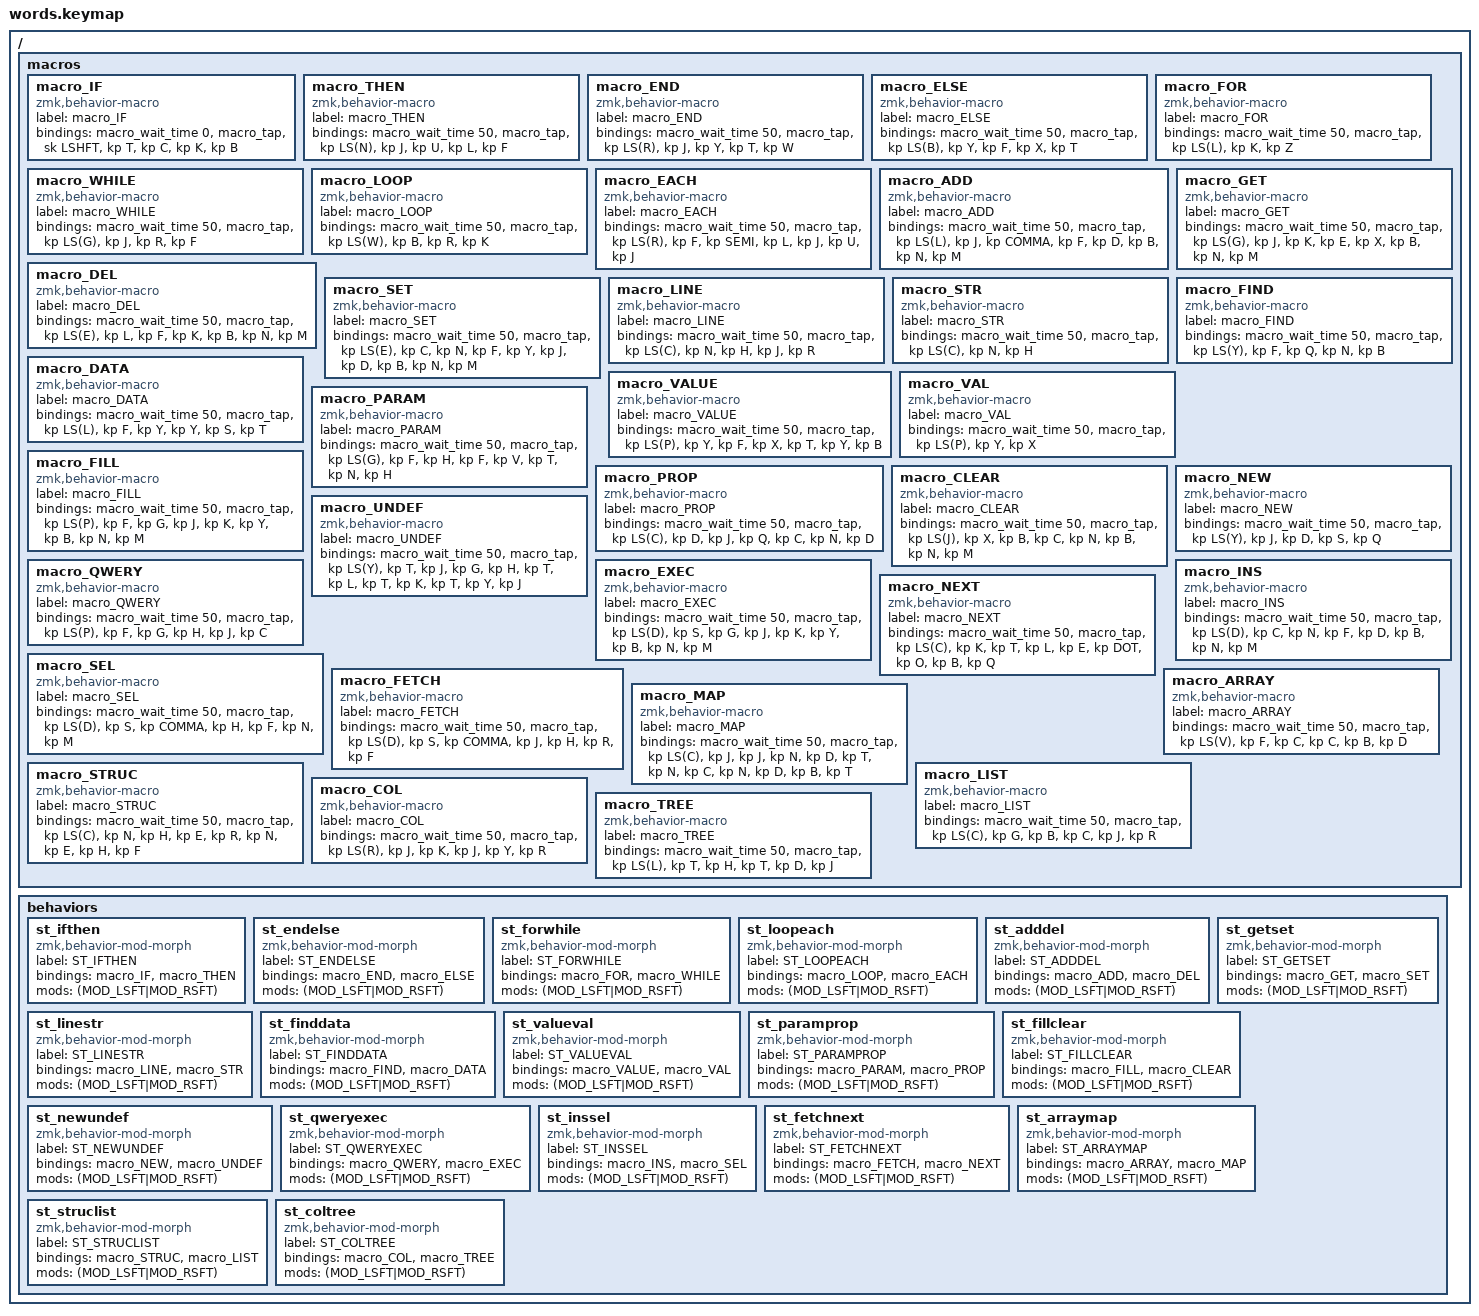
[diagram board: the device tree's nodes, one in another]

/ {
    macros {
        macro_IF: macro_IF {
            label = "macro_IF";
            compatible = "zmk,behavior-macro";
            #binding-cells = <0>;
            bindings
                = <&macro_wait_time 0>
                , <&macro_tap &sk LSHFT &kp T &kp C &kp K &kp B>
                ;
        };
        macro_THEN: macro_THEN {
            label = "macro_THEN";
            compatible = "zmk,behavior-macro";
            #binding-cells = <0>;
            bindings
                = <&macro_wait_time 50>
                , <&macro_tap &kp LS(N) &kp J &kp U &kp L &kp F>
                ;
        };
    };
};
/ {
    behaviors {
        st_ifthen: st_ifthen {
            compatible = "zmk,behavior-mod-morph";
            label = "ST_IFTHEN";
            #binding-cells = <0>;
            bindings = <&macro_IF>, <&macro_THEN>;
            mods = <(MOD_LSFT|MOD_RSFT)>;
        };
    };
};
/ {
    macros {
        macro_END: macro_END {
            label = "macro_END";
            compatible = "zmk,behavior-macro";
            #binding-cells = <0>;
            bindings
                = <&macro_wait_time 50>
                , <&macro_tap &kp LS(R) &kp J &kp Y &kp T &kp W>
                ;
        };
        macro_ELSE: macro_ELSE {
            label = "macro_ELSE";
            compatible = "zmk,behavior-macro";
            #binding-cells = <0>;
            bindings
                = <&macro_wait_time 50>
                , <&macro_tap &kp LS(B) &kp Y &kp F &kp X &kp T>
                ;
        };
    };
};
/ {
    behaviors {
        st_endelse: st_endelse {
            compatible = "zmk,behavior-mod-morph";
            label = "ST_ENDELSE";
            #binding-cells = <0>;
            bindings = <&macro_END>, <&macro_ELSE>;
            mods = <(MOD_LSFT|MOD_RSFT)>;
        };
    };
};
/ {
    macros {
        macro_FOR: macro_FOR {
            label = "macro_FOR";
            compatible = "zmk,behavior-macro";
            #binding-cells = <0>;
            bindings
                = <&macro_wait_time 50>
                , <&macro_tap &kp LS(L) &kp K &kp Z>
                ;
        };
        macro_WHILE: macro_WHILE {
            label = "macro_WHILE";
            compatible = "zmk,behavior-macro";
            #binding-cells = <0>;
            bindings
                = <&macro_wait_time 50>
                , <&macro_tap &kp LS(G) &kp J &kp R &kp F>
                ;
        };
    };
};
/ {
    behaviors {
        st_forwhile: st_forwhile {
            compatible = "zmk,behavior-mod-morph";
            label = "ST_FORWHILE";
            #binding-cells = <0>;
            bindings = <&macro_FOR>, <&macro_WHILE>;
            mods = <(MOD_LSFT|MOD_RSFT)>;
        };
    };
};
/ {
    macros {
        macro_LOOP: macro_LOOP {
            label = "macro_LOOP";
            compatible = "zmk,behavior-macro";
            #binding-cells = <0>;
            bindings
                = <&macro_wait_time 50>
                , <&macro_tap &kp LS(W) &kp B &kp R &kp K>
                ;
        };
        macro_EACH: macro_EACH {
            label = "macro_EACH";
            compatible = "zmk,behavior-macro";
            #binding-cells = <0>;
            bindings
                = <&macro_wait_time 50>
                , <&macro_tap &kp LS(R) &kp F &kp SEMI &kp L &kp J &kp U &kp J>
                ;
        };
    };
};
/ {
    behaviors {
        st_loopeach: st_loopeach {
            compatible = "zmk,behavior-mod-morph";
            label = "ST_LOOPEACH";
            #binding-cells = <0>;
            bindings = <&macro_LOOP>, <&macro_EACH>;
            mods = <(MOD_LSFT|MOD_RSFT)>;
        };
    };
};
/ {
    macros {
        macro_ADD: macro_ADD {
            label = "macro_ADD";
            compatible = "zmk,behavior-macro";
            #binding-cells = <0>;
            bindings
                = <&macro_wait_time 50>
                , <&macro_tap &kp LS(L) &kp J &kp COMMA &kp F &kp D &kp B &kp N &kp M>
                ;
        };
        macro_DEL: macro_DEL {
            label = "macro_DEL";
            compatible = "zmk,behavior-macro";
            #binding-cells = <0>;
            bindings
                = <&macro_wait_time 50>
                , <&macro_tap &kp LS(E) &kp L &kp F &kp K &kp B &kp N &kp M>
                ;
        };
    };
};
/ {
    behaviors {
        st_adddel: st_adddel {
            compatible = "zmk,behavior-mod-morph";
            label = "ST_ADDDEL";
            #binding-cells = <0>;
            bindings = <&macro_ADD>, <&macro_DEL>;
            mods = <(MOD_LSFT|MOD_RSFT)>;
        };
    };
};
/ {
    macros {
        macro_GET: macro_GET {
            label = "macro_GET";
            compatible = "zmk,behavior-macro";
            #binding-cells = <0>;
            bindings
                = <&macro_wait_time 50>
                , <&macro_tap &kp LS(G) &kp J &kp K &kp E &kp X &kp B &kp N &kp M>
                ;
        };
        macro_SET: macro_SET {
            label = "macro_SET";
            compatible = "zmk,behavior-macro";
            #binding-cells = <0>;
            bindings
                = <&macro_wait_time 50>
                , <&macro_tap &kp LS(E) &kp C &kp N &kp F &kp Y &kp J &kp D &kp B &kp N &kp M>
                ;
        };
    };
};
/ {
    behaviors {
        st_getset: st_getset {
            compatible = "zmk,behavior-mod-morph";
            label = "ST_GETSET";
            #binding-cells = <0>;
            bindings = <&macro_GET>, <&macro_SET>;
            mods = <(MOD_LSFT|MOD_RSFT)>;
        };
    };
};
/ {
    macros {
        macro_LINE: macro_LINE {
            label = "macro_LINE";
            compatible = "zmk,behavior-macro";
            #binding-cells = <0>;
            bindings
                = <&macro_wait_time 50>
                , <&macro_tap &kp LS(C) &kp N &kp H &kp J &kp R>
                ;
        };
        macro_STR: macro_STR {
            label = "macro_STR";
            compatible = "zmk,behavior-macro";
            #binding-cells = <0>;
            bindings
                = <&macro_wait_time 50>
                , <&macro_tap &kp LS(C) &kp N &kp H>
                ;
        };
    };
};
/ {
    behaviors {
        st_linestr: st_linestr {
            compatible = "zmk,behavior-mod-morph";
            label = "ST_LINESTR";
            #binding-cells = <0>;
            bindings = <&macro_LINE>, <&macro_STR>;
            mods = <(MOD_LSFT|MOD_RSFT)>;
        };
    };
};
/ {
    macros {
        macro_FIND: macro_FIND {
            label = "macro_FIND";
            compatible = "zmk,behavior-macro";
            #binding-cells = <0>;
            bindings
                = <&macro_wait_time 50>
                , <&macro_tap &kp LS(Y) &kp F &kp Q &kp N &kp B>
                ;
        };
        macro_DATA: macro_DATA {
            label = "macro_DATA";
            compatible = "zmk,behavior-macro";
            #binding-cells = <0>;
            bindings
                = <&macro_wait_time 50>
                , <&macro_tap &kp LS(L) &kp F &kp Y &kp Y &kp S &kp T>
                ;
        };
    };
};
/ {
    behaviors {
        st_finddata: st_finddata {
            compatible = "zmk,behavior-mod-morph";
            label = "ST_FINDDATA";
            #binding-cells = <0>;
            bindings = <&macro_FIND>, <&macro_DATA>;
            mods = <(MOD_LSFT|MOD_RSFT)>;
        };
    };
};
/ {
    macros {
        macro_VALUE: macro_VALUE {
            label = "macro_VALUE";
            compatible = "zmk,behavior-macro";
            #binding-cells = <0>;
            bindings
                = <&macro_wait_time 50>
                , <&macro_tap &kp LS(P) &kp Y &kp F &kp X &kp T &kp Y &kp B>
                ;
        };
        macro_VAL: macro_VAL {
            label = "macro_VAL";
            compatible = "zmk,behavior-macro";
            #binding-cells = <0>;
            bindings
                = <&macro_wait_time 50>
                , <&macro_tap &kp LS(P) &kp Y &kp X>
                ;
        };
    };
};
/ {
    behaviors {
        st_valueval: st_valueval {
            compatible = "zmk,behavior-mod-morph";
            label = "ST_VALUEVAL";
            #binding-cells = <0>;
            bindings = <&macro_VALUE>, <&macro_VAL>;
            mods = <(MOD_LSFT|MOD_RSFT)>;
        };
    };
};
/ {
    macros {
        macro_PARAM: macro_PARAM {
            label = "macro_PARAM";
            compatible = "zmk,behavior-macro";
            #binding-cells = <0>;
            bindings
                = <&macro_wait_time 50>
                , <&macro_tap &kp LS(G) &kp F &kp H &kp F &kp V &kp T &kp N &kp H>
                ;
        };
        macro_PROP: macro_PROP {
            label = "macro_PROP";
            compatible = "zmk,behavior-macro";
            #binding-cells = <0>;
            bindings
                = <&macro_wait_time 50>
                , <&macro_tap &kp LS(C) &kp D &kp J &kp Q &kp C &kp N &kp D>
                ;
        };
    };
};
/ {
    behaviors {
        st_paramprop: st_paramprop {
            compatible = "zmk,behavior-mod-morph";
            label = "ST_PARAMPROP";
            #binding-cells = <0>;
            bindings = <&macro_PARAM>, <&macro_PROP>;
            mods = <(MOD_LSFT|MOD_RSFT)>;
        };
    };
};
/ {
    macros {
        macro_FILL: macro_FILL {
            label = "macro_FILL";
            compatible = "zmk,behavior-macro";
            #binding-cells = <0>;
            bindings
                = <&macro_wait_time 50>
                , <&macro_tap &kp LS(P) &kp F &kp G &kp J &kp K &kp Y &kp B &kp N &kp M>
                ;
        };
        macro_CLEAR: macro_CLEAR {
            label = "macro_CLEAR";
            compatible = "zmk,behavior-macro";
            #binding-cells = <0>;
            bindings
                = <&macro_wait_time 50>
                , <&macro_tap &kp LS(J) &kp X &kp B &kp C &kp N &kp B &kp N &kp M>
                ;
        };
    };
};
/ {
    behaviors {
        st_fillclear: st_fillclear {
            compatible = "zmk,behavior-mod-morph";
            label = "ST_FILLCLEAR";
            #binding-cells = <0>;
            bindings = <&macro_FILL>, <&macro_CLEAR>;
            mods = <(MOD_LSFT|MOD_RSFT)>;
        };
    };
};
/ {
    macros {
        macro_NEW: macro_NEW {
            label = "macro_NEW";
            compatible = "zmk,behavior-macro";
            #binding-cells = <0>;
            bindings
                = <&macro_wait_time 50>
                , <&macro_tap &kp LS(Y) &kp J &kp D &kp S &kp Q>
                ;
        };
        macro_UNDEF: macro_UNDEF {
            label = "macro_UNDEF";
            compatible = "zmk,behavior-macro";
            #binding-cells = <0>;
            bindings
                = <&macro_wait_time 50>
                , <&macro_tap &kp LS(Y) &kp T &kp J &kp G &kp H &kp T &kp L &kp T &kp K &kp T &kp Y &kp J>
                ;
        };
    };
};
/ {
    behaviors {
        st_newundef: st_newundef {
            compatible = "zmk,behavior-mod-morph";
            label = "ST_NEWUNDEF";
            #binding-cells = <0>;
            bindings = <&macro_NEW>, <&macro_UNDEF>;
            mods = <(MOD_LSFT|MOD_RSFT)>;
        };
    };
};
/ {
    macros {
        macro_QWERY: macro_QWERY {
            label = "macro_QWERY";
            compatible = "zmk,behavior-macro";
            #binding-cells = <0>;
            bindings
                = <&macro_wait_time 50>
                , <&macro_tap &kp LS(P) &kp F &kp G &kp H &kp J &kp C>
                ;
        };
        macro_EXEC: macro_EXEC {
            label = "macro_EXEC";
            compatible = "zmk,behavior-macro";
            #binding-cells = <0>;
            bindings
                = <&macro_wait_time 50>
                , <&macro_tap &kp LS(D) &kp S &kp G &kp J &kp K &kp Y &kp B &kp N &kp M>
                ;
        };
    };
};
/ {
    behaviors {
        st_qweryexec: st_qweryexec {
            compatible = "zmk,behavior-mod-morph";
            label = "ST_QWERYEXEC";
            #binding-cells = <0>;
            bindings = <&macro_QWERY>, <&macro_EXEC>;
            mods = <(MOD_LSFT|MOD_RSFT)>;
        };
    };
};
/ {
    macros {
        macro_INS: macro_INS {
            label = "macro_INS";
            compatible = "zmk,behavior-macro";
            #binding-cells = <0>;
            bindings
                = <&macro_wait_time 50>
                , <&macro_tap &kp LS(D) &kp C &kp N &kp F &kp D &kp B &kp N &kp M>
                ;
        };
        macro_SEL: macro_SEL {
            label = "macro_SEL";
            compatible = "zmk,behavior-macro";
            #binding-cells = <0>;
            bindings
                = <&macro_wait_time 50>
                , <&macro_tap &kp LS(D) &kp S &kp COMMA &kp H &kp F &kp N &kp M>
                ;
        };
    };
};
/ {
    behaviors {
        st_inssel: st_inssel {
            compatible = "zmk,behavior-mod-morph";
            label = "ST_INSSEL";
            #binding-cells = <0>;
            bindings = <&macro_INS>, <&macro_SEL>;
            mods = <(MOD_LSFT|MOD_RSFT)>;
        };
    };
};
/ {
    macros {
        macro_FETCH: macro_FETCH {
            label = "macro_FETCH";
            compatible = "zmk,behavior-macro";
            #binding-cells = <0>;
            bindings
                = <&macro_wait_time 50>
                , <&macro_tap &kp LS(D) &kp S &kp COMMA &kp J &kp H &kp R &kp F>
                ;
        };
        macro_NEXT: macro_NEXT {
            label = "macro_NEXT";
            compatible = "zmk,behavior-macro";
            #binding-cells = <0>;
            bindings
                = <&macro_wait_time 50>
                , <&macro_tap &kp LS(C) &kp K &kp T &kp L &kp E &kp DOT &kp O &kp B &kp Q>
                ;
        };
    };
};
/ {
    behaviors {
        st_fetchnext: st_fetchnext {
            compatible = "zmk,behavior-mod-morph";
            label = "ST_FETCHNEXT";
            #binding-cells = <0>;
            bindings = <&macro_FETCH>, <&macro_NEXT>;
            mods = <(MOD_LSFT|MOD_RSFT)>;
        };
    };
};
/ {
    macros {
        macro_ARRAY: macro_ARRAY {
            label = "macro_ARRAY";
            compatible = "zmk,behavior-macro";
            #binding-cells = <0>;
            bindings
                = <&macro_wait_time 50>
                , <&macro_tap &kp LS(V) &kp F &kp C &kp C &kp B &kp D>
                ;
        };
        macro_MAP: macro_MAP {
            label = "macro_MAP";
            compatible = "zmk,behavior-macro";
            #binding-cells = <0>;
            bindings
                = <&macro_wait_time 50>
                , <&macro_tap &kp LS(C) &kp J &kp J &kp N &kp D &kp T &kp N &kp C &kp N &kp D &kp B &kp T>
                ;
        };
    };
};
/ {
    behaviors {
        st_arraymap: st_arraymap {
            compatible = "zmk,behavior-mod-morph";
            label = "ST_ARRAYMAP";
            #binding-cells = <0>;
            bindings = <&macro_ARRAY>, <&macro_MAP>;
            mods = <(MOD_LSFT|MOD_RSFT)>;
        };
    };
};
/ {
    macros {
        macro_STRUC: macro_STRUC {
            label = "macro_STRUC";
            compatible = "zmk,behavior-macro";
            #binding-cells = <0>;
            bindings
                = <&macro_wait_time 50>
                , <&macro_tap &kp LS(C) &kp N &kp H &kp E &kp R &kp N &kp E &kp H &kp F>
                ;
        };
        macro_LIST: macro_LIST {
            label = "macro_LIST";
            compatible = "zmk,behavior-macro";
            #binding-cells = <0>;
            bindings
                = <&macro_wait_time 50>
                , <&macro_tap &kp LS(C) &kp G &kp B &kp C &kp J &kp R>
                ;
        };
    };
};
/ {
    behaviors {
        st_struclist: st_struclist {
            compatible = "zmk,behavior-mod-morph";
            label = "ST_STRUCLIST";
            #binding-cells = <0>;
            bindings = <&macro_STRUC>, <&macro_LIST>;
            mods = <(MOD_LSFT|MOD_RSFT)>;
        };
    };
};
/ {
    macros {
        macro_COL: macro_COL {
            label = "macro_COL";
            compatible = "zmk,behavior-macro";
            #binding-cells = <0>;
            bindings
                = <&macro_wait_time 50>
                , <&macro_tap &kp LS(R) &kp J &kp K &kp J &kp Y &kp R>
                ;
        };
        macro_TREE: macro_TREE {
            label = "macro_TREE";
            compatible = "zmk,behavior-macro";
            #binding-cells = <0>;
            bindings
                = <&macro_wait_time 50>
                , <&macro_tap &kp LS(L) &kp T &kp H &kp T &kp D &kp J>
                ;
        };
    };
};
/ {
    behaviors {
        st_coltree: st_coltree {
            compatible = "zmk,behavior-mod-morph";
            label = "ST_COLTREE";
            #binding-cells = <0>;
            bindings = <&macro_COL>, <&macro_TREE>;
            mods = <(MOD_LSFT|MOD_RSFT)>;
        };
    };
};
